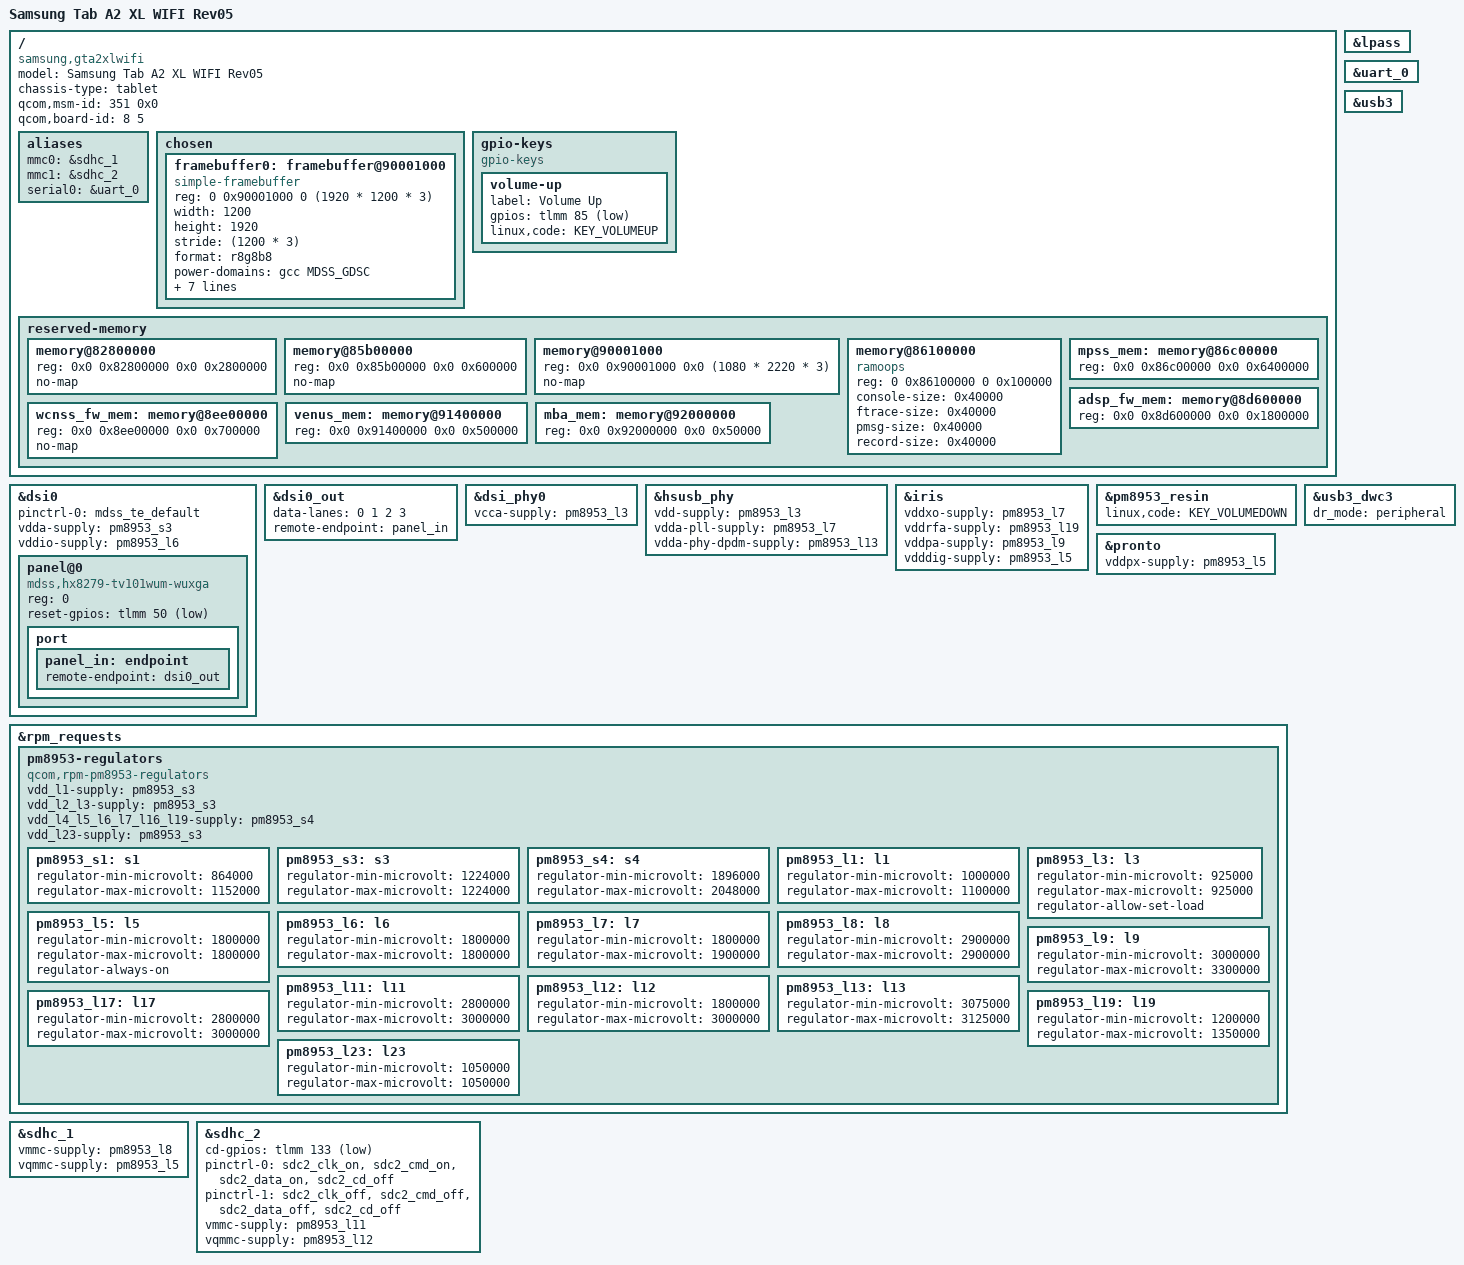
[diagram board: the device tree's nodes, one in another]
// SPDX-License-Identifier: BSD-3-Clause
// Copyright (c) 2022, The Linux Foundation. All rights reserved.

/dts-v1/;

#include "msm8953.dtsi"
#include "pm8953.dtsi"

/ {
	model = "Samsung Tab A2 XL WIFI Rev05";
	compatible = "samsung,gta2xlwifi", "qcom,sdm450";
	chassis-type = "tablet";
	qcom,msm-id = <351 0x0>;
	qcom,board-id = <8 5>;

	aliases {
		mmc0 = &sdhc_1;
		mmc1 = &sdhc_2;
		serial0 = &uart_0;
	};

	chosen {
		#address-cells = <2>;
		#size-cells = <2>;
		ranges;

		framebuffer0: framebuffer@90001000 {
			compatible = "simple-framebuffer";
			reg = <0 0x90001000 0 (1920 * 1200 * 3)>;

			width = <1200>;
			height = <1920>;
			stride = <(1200 * 3)>;
			format = "r8g8b8";

			power-domains = <&gcc MDSS_GDSC>;

			clocks = <&gcc GCC_MDSS_AHB_CLK>,
				 <&gcc GCC_MDSS_AXI_CLK>,
				 <&gcc GCC_MDSS_VSYNC_CLK>,
				 <&gcc GCC_MDSS_MDP_CLK>,
				 <&gcc GCC_MDSS_BYTE0_CLK>,
				 <&gcc GCC_MDSS_PCLK0_CLK>,
				 <&gcc GCC_MDSS_ESC0_CLK>;
		};
	};

	gpio-keys {
		compatible = "gpio-keys";

		volume-up {
			label = "Volume Up";
			gpios = <&tlmm 85 GPIO_ACTIVE_LOW>;
			linux,code = <KEY_VOLUMEUP>;
		};
	};

	reserved-memory {
		memory@82800000 {
			reg = <0x0 0x82800000 0x0 0x2800000>;
			no-map;
		};

		memory@85b00000 {
			reg = <0x0 0x85b00000 0x0 0x600000>;
			no-map;
		};

		memory@90001000 {
			reg = <0x0 0x90001000 0x0 (1080 * 2220 * 3)>;
			no-map;
		};

		memory@86100000 {
			compatible = "ramoops";
			reg = <0 0x86100000 0 0x100000>;

			console-size = <0x40000>;
			ftrace-size = <0x40000>;
			pmsg-size = <0x40000>;
			record-size = <0x40000>;
		};

		mpss_mem: memory@86c00000 {
			reg = <0x0 0x86c00000 0x0 0x6400000>;
		};

		adsp_fw_mem: memory@8d600000  {
			reg = <0x0 0x8d600000 0x0 0x1800000>;
		};

		/delete-node/memory@8e700000;
		wcnss_fw_mem: memory@8ee00000 {
			reg = <0x0 0x8ee00000 0x0 0x700000>;
			no-map;
		};

		venus_mem: memory@91400000 {
			reg = <0x0 0x91400000 0x0 0x500000>;
		};

		mba_mem: memory@92000000 {
			reg = <0x0 0x92000000 0x0 0x50000>;
		};
	};

};

&dsi0 {
	status = "okay";

	pinctrl-names = "default";
	pinctrl-0 = <&mdss_te_default>;

	vdda-supply = <&pm8953_s3>;
	vddio-supply = <&pm8953_l6>;

	panel@0 {
		compatible = "mdss,hx8279-tv101wum-wuxga";
		reg = <0>;

		reset-gpios = <&tlmm 50 GPIO_ACTIVE_LOW>;

		port {
			panel_in: endpoint {
				remote-endpoint = <&dsi0_out>;
			};
		};
	};
};

&dsi0_out {
	data-lanes = <0 1 2 3>;
	remote-endpoint = <&panel_in>;
};

&dsi_phy0 {
	vcca-supply = <&pm8953_l3>;
};

&hsusb_phy {
	status = "okay";

	vdd-supply = <&pm8953_l3>;
	vdda-pll-supply = <&pm8953_l7>;
	vdda-phy-dpdm-supply = <&pm8953_l13>;
};

&iris {
	vddxo-supply = <&pm8953_l7>;
	vddrfa-supply = <&pm8953_l19>;
	vddpa-supply = <&pm8953_l9>;
	vdddig-supply = <&pm8953_l5>;
};

&lpass {
	status = "okay";
};

&pm8953_resin {
	status = "okay";
	linux,code = <KEY_VOLUMEDOWN>;
};

&pronto {
	status = "okay";
	
	vddpx-supply = <&pm8953_l5>;
};


&rpm_requests {
	pm8953-regulators {
		compatible = "qcom,rpm-pm8953-regulators";

		vdd_l1-supply = <&pm8953_s3>;
		vdd_l2_l3-supply = <&pm8953_s3>;
		vdd_l4_l5_l6_l7_l16_l19-supply = <&pm8953_s4>;
		vdd_l23-supply = <&pm8953_s3>;

		pm8953_s1: s1 {
			regulator-min-microvolt = <864000>;
			regulator-max-microvolt = <1152000>;
		};

		pm8953_s3: s3 {
			regulator-min-microvolt = <1224000>;
			regulator-max-microvolt = <1224000>;
		};

		pm8953_s4: s4 {
			regulator-min-microvolt = <1896000>;
			regulator-max-microvolt = <2048000>;
		};

		pm8953_l1: l1 {
			regulator-min-microvolt = <1000000>;
			regulator-max-microvolt = <1100000>;
		};

		pm8953_l3: l3 {
			regulator-min-microvolt = <925000>;
			regulator-max-microvolt = <925000>;
			regulator-allow-set-load;
		};

		pm8953_l5: l5 {
			regulator-min-microvolt = <1800000>;
			regulator-max-microvolt = <1800000>;
			regulator-always-on;
		};

		pm8953_l6: l6 {
			regulator-min-microvolt = <1800000>;
			regulator-max-microvolt = <1800000>;
		};

		pm8953_l7: l7 {
			regulator-min-microvolt = <1800000>;
			regulator-max-microvolt = <1900000>;
		};

		pm8953_l8: l8 {
			regulator-min-microvolt = <2900000>;
			regulator-max-microvolt = <2900000>;
		};

		pm8953_l9: l9 {
			regulator-min-microvolt = <3000000>;
			regulator-max-microvolt = <3300000>;
		};

		pm8953_l11: l11 {
			regulator-min-microvolt = <2800000>;
			regulator-max-microvolt = <3000000>;
		};

		pm8953_l12: l12 {
			regulator-min-microvolt = <1800000>;
			regulator-max-microvolt = <3000000>;
		};

		pm8953_l13: l13 {
			regulator-min-microvolt = <3075000>;
			regulator-max-microvolt = <3125000>;
		};

		pm8953_l17: l17 {
			regulator-min-microvolt = <2800000>;
			regulator-max-microvolt = <3000000>;
		};

		pm8953_l19: l19 {
			regulator-min-microvolt = <1200000>;
			regulator-max-microvolt = <1350000>;
		};

		pm8953_l23: l23 {
			regulator-min-microvolt = <1050000>;
			regulator-max-microvolt = <1050000>;
		};
	};
};

&sdhc_1 {
	status = "okay";

	vmmc-supply = <&pm8953_l8>;
	vqmmc-supply = <&pm8953_l5>;
};

&sdhc_2 {
	status = "okay";

	cd-gpios = <&tlmm 133 GPIO_ACTIVE_LOW>;

	pinctrl-names = "default", "sleep";
	pinctrl-0 = <&sdc2_clk_on &sdc2_cmd_on &sdc2_data_on &sdc2_cd_off>;
	pinctrl-1 = <&sdc2_clk_off &sdc2_cmd_off &sdc2_data_off &sdc2_cd_off>;

	vmmc-supply = <&pm8953_l11>;
	vqmmc-supply = <&pm8953_l12>;
};

&uart_0 {
	status = "okay";
};

&usb3 {
	status = "okay";
};

&usb3_dwc3 {
	dr_mode = "peripheral";
};
